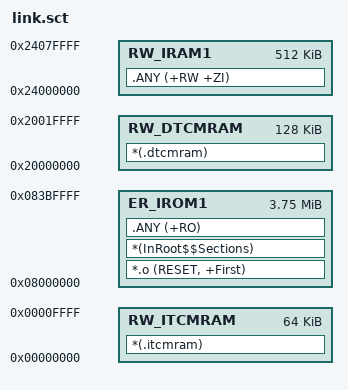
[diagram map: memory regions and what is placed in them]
; *************************************************************
; *** Scatter-Loading Description File generated by uVision ***
; *************************************************************

LR_IROM1 0x08000000 0x003C0000  {    ; load region size_region - GD32H75E Flash 3840KB
  ER_IROM1 0x08000000 0x003C0000  {  ; load address = execution address
   *.o (RESET, +First)
   *(InRoot$$Sections)
   .ANY (+RO)
  }
  RW_IRAM1 0x24000000 0x00080000  {  ; RW data - GD32H75E AXI SRAM 512KB at 0x24000000
   .ANY (+RW +ZI)
  }
  RW_ITCMRAM 0x00000000 0x00010000  {  ; ITCM RAM (64KB)
   *(.itcmram)
  }
  RW_DTCMRAM 0x20000000 0x00020000  {  ; DTCM RAM (128KB)
   *(.dtcmram)
  }
}

